# MK10D5 register map
File version: 1.6
Registers are 8-bit, read-write, reset 0x0 unless marked. A register's access mark holds for its fields unless they carry their own. Offsets are from the block's base; [hi:lo] are bit positions; {n}, {i} and the like mark numbered series; 'fields as' and 'values as' point back to an identical list.

## DMA — Enhanced direct memory access controller
Base 0x40008000; register names take the prefix DMA_
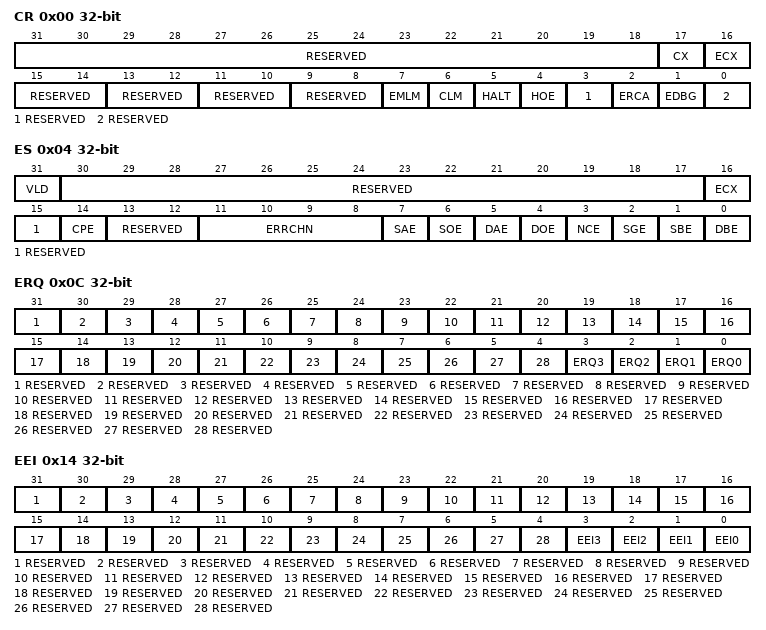
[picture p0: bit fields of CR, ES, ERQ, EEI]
0x00 CR 32-bit access per field — Control Register
  [31:18] RESERVED ro
  [17] CX rw — Cancel Transfer
    0=Normal operation; 1=Cancel the remaining data transfer. Stop the executing channel and force the minor loop to finish. The cancel takes effect after the last write of the current read/write sequence. The CX bit clears itself after the cancel has been honored. This cancel retires the channel normally as if the minor loop was completed.
  [16] ECX rw — Error Cancel Transfer
    0=Normal operation; 1=Cancel the remaining data transfer in the same fashion as the CX bit. Stop the executing channel and force the minor loop to finish. The cancel takes effect after the last write of the current read/write sequence. The ECX bit clears itself after the cancel is honored. In addition to cancelling the transfer, ECX treats the cancel as an error condition, thus updating the ES register and generating an optional error interrupt.
  [15:14] RESERVED ro
  [13:12] RESERVED ro
  [11:10] RESERVED ro
  [9:8] RESERVED ro
  [7] EMLM rw — Enable Minor Loop Mapping
    0=Disabled. TCDn.word2 is defined as a 32-bit NBYTES field.; 1=Enabled. TCDn.word2 is redefined to include individual enable fields, an offset field, and the NBYTES field. The individual enable fields allow the minor loop offset to be applied to the source address, the destination address, or both. The NBYTES field is reduced when either offset is enabled.
  [6] CLM rw — Continuous Link Mode
    0=A minor loop channel link made to itself goes through channel arbitration before being activated again; 1=A minor loop channel link made to itself does not go through channel arbitration before being activated again. Upon minor loop completion, the channel activates again if that channel has a minor loop channel link enabled and the link channel is itself. This effectively applies the minor loop offsets and restarts the next minor loop.
  [5] HALT rw — Halt DMA Operations
    0=Normal operation; 1=Stall the start of any new channels. Executing channels are allowed to complete. Channel execution resumes when this bit is cleared.
  [4] HOE rw — Halt On Error
    0=Normal operation; 1=Any error causes the HALT bit to set. Subsequently, all service requests are ignored until the HALT bit is cleared.
  [3] RESERVED ro
  [2] ERCA rw — Enable Round Robin Channel Arbitration
    0=Fixed priority arbitration is used for channel selection; 1=Round robin arbitration is used for channel selection
  [1] EDBG rw — Enable Debug
    0=When in debug mode, the DMA continues to operate; 1=When in debug mode, the DMA stalls the start of a new channel. Executing channels are allowed to complete. Channel execution resumes when the system exits debug mode or the EDBG bit is cleared.
  [0] RESERVED ro
0x04 ES 32-bit ro — Error Status Register
  [31] VLD
    0=No ERR bits are set; 1=At least one ERR bit is set indicating a valid error exists that has not been cleared
  [30:17] RESERVED
  [16] ECX — Transfer Cancelled
    0=No cancelled transfers; 1=The last recorded entry was a cancelled transfer by the error cancel transfer input
  [15] RESERVED
  [14] CPE — Channel Priority Error
    0=No channel priority error; 1=The last recorded error was a configuration error in the channel priorities. Channel priorities are not unique.
  [13:12] RESERVED
  [11:8] ERRCHN — Error Channel Number or Cancelled Channel Number
  [7] SAE — Source Address Error
    0=No source address configuration error; 1=The last recorded error was a configuration error detected in the TCDn_SADDR field. TCDn_SADDR is inconsistent with TCDn_ATTR[SSIZE].
  [6] SOE — Source Offset Error
    0=No source offset configuration error; 1=The last recorded error was a configuration error detected in the TCDn_SOFF field. TCDn_SOFF is inconsistent with TCDn_ATTR[SSIZE].
  [5] DAE — Destination Address Error
    0=No destination address configuration error; 1=The last recorded error was a configuration error detected in the TCDn_DADDR field. TCDn_DADDR is inconsistent with TCDn_ATTR[DSIZE].
  [4] DOE — Destination Offset Error
    0=No destination offset configuration error; 1=The last recorded error was a configuration error detected in the TCDn_DOFF field. TCDn_DOFF is inconsistent with TCDn_ATTR[DSIZE].
  [3] NCE — NBYTES/CITER Configuration Error
    0=No NBYTES/CITER configuration error; 1=The last recorded error was a configuration error detected in the TCDn_NBYTES or TCDn_CITER fields. TCDn_NBYTES is not a multiple of TCDn_ATTR[SSIZE] and TCDn_ATTR[DSIZE], or TCDn_CITER[CITER] is equal to zero, or TCDn_CITER[ELINK] is not equal to TCDn_BITER[ELINK]
  [2] SGE — Scatter/Gather Configuration Error
    0=No scatter/gather configuration error; 1=The last recorded error was a configuration error detected in the TCDn_DLASTSGA field. This field is checked at the beginning of a scatter/gather operation after major loop completion if TCDn_CSR[ESG] is enabled. TCDn_DLASTSGA is not on a 32 byte boundary.
  [1] SBE — Source Bus Error
    0=No source bus error; 1=The last recorded error was a bus error on a source read
  [0] DBE — Destination Bus Error
    0=No destination bus error; 1=The last recorded error was a bus error on a destination write
0x0C ERQ 32-bit — Enable Request Register
  [31] RESERVED
  [30] RESERVED
  [29] RESERVED
  [28] RESERVED
  [27] RESERVED
  [26] RESERVED
  [25] RESERVED
  [24] RESERVED
  [23] RESERVED
  [22] RESERVED
  [21] RESERVED
  [20] RESERVED
  [19] RESERVED
  [18] RESERVED
  [17] RESERVED
  [16] RESERVED
  [15] RESERVED
  [14] RESERVED
  [13] RESERVED
  [12] RESERVED
  [11] RESERVED
  [10] RESERVED
  [9] RESERVED
  [8] RESERVED
  [7] RESERVED
  [6] RESERVED
  [5] RESERVED
  [4] RESERVED
  [n] ERQ{n} (n=0..3) — Enable DMA Request {n}
    0=The DMA request signal for the corresponding channel is disabled; 1=The DMA request signal for the corresponding channel is enabled
0x14 EEI 32-bit — Enable Error Interrupt Register
  [31] RESERVED
  [30] RESERVED
  [29] RESERVED
  [28] RESERVED
  [27] RESERVED
  [26] RESERVED
  [25] RESERVED
  [24] RESERVED
  [23] RESERVED
  [22] RESERVED
  [21] RESERVED
  [20] RESERVED
  [19] RESERVED
  [18] RESERVED
  [17] RESERVED
  [16] RESERVED
  [15] RESERVED
  [14] RESERVED
  [13] RESERVED
  [12] RESERVED
  [11] RESERVED
  [10] RESERVED
  [9] RESERVED
  [8] RESERVED
  [7] RESERVED
  [6] RESERVED
  [5] RESERVED
  [4] RESERVED
  [n] EEI{n} (n=0..3) — Enable Error Interrupt {n}
    0=The error signal for corresponding channel does not generate an error interrupt; 1=The assertion of the error signal for corresponding channel generates an error interrupt request
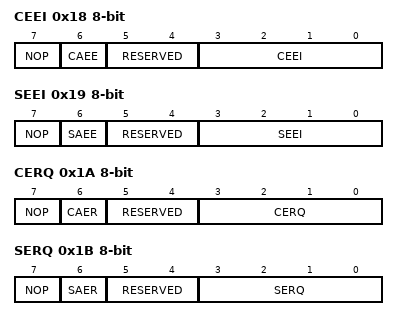
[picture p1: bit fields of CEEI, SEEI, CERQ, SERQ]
0x18 CEEI wo — Clear Enable Error Interrupt Register
  [7] NOP
    0=Normal operation; 1=No operation, ignore the other bits in this register
  [6] CAEE — Clear All Enable Error Interrupts
    0=Clear only the EEI bit specified in the CEEI field; 1=Clear all bits in EEI
  [5:4] RESERVED
  [3:0] CEEI — Clear Enable Error Interrupt
0x19 SEEI wo — Set Enable Error Interrupt Register
  [7] NOP
    values as CEEI.NOP
  [6] SAEE — Sets All Enable Error Interrupts
    0=Set only the EEI bit specified in the SEEI field; 1=Sets all bits in EEI
  [5:4] RESERVED
  [3:0] SEEI — Set Enable Error Interrupt
0x1A CERQ wo — Clear Enable Request Register
  [7] NOP
    values as CEEI.NOP
  [6] CAER — Clear All Enable Requests
    0=Clear only the ERQ bit specified in the CERQ field; 1=Clear all bits in ERQ
  [5:4] RESERVED
  [3:0] CERQ — Clear Enable Request
0x1B SERQ wo — Set Enable Request Register
  [7] NOP
    values as CEEI.NOP
  [6] SAER — Set All Enable Requests
    0=Set only the ERQ bit specified in the SERQ field; 1=Set all bits in ERQ
  [5:4] RESERVED
  [3:0] SERQ — Set enable request
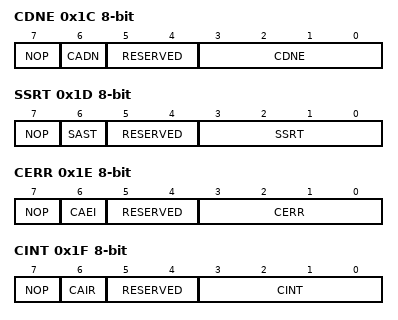
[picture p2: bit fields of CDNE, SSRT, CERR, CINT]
0x1C CDNE wo — Clear DONE Status Bit Register
  [7] NOP
    values as CEEI.NOP
  [6] CADN — Clears All DONE Bits
    0=Clears only the TCDn_CSR[DONE] bit specified in the CDNE field; 1=Clears all bits in TCDn_CSR[DONE]
  [5:4] RESERVED
  [3:0] CDNE — Clear DONE Bit
0x1D SSRT wo — Set START Bit Register
  [7] NOP
    values as CEEI.NOP
  [6] SAST — Set All START Bits (activates all channels)
    0=Set only the TCDn_CSR[START] bit specified in the SSRT field; 1=Set all bits in TCDn_CSR[START]
  [5:4] RESERVED
  [3:0] SSRT — Set START Bit
0x1E CERR wo — Clear Error Register
  [7] NOP
    values as CEEI.NOP
  [6] CAEI — Clear All Error Indicators
    0=Clear only the ERR bit specified in the CERR field; 1=Clear all bits in ERR
  [5:4] RESERVED
  [3:0] CERR — Clear Error Indicator
0x1F CINT wo — Clear Interrupt Request Register
  [7] NOP
    values as CEEI.NOP
  [6] CAIR — Clear All Interrupt Requests
    0=Clear only the INT bit specified in the CINT field; 1=Clear all bits in INT
  [5:4] RESERVED
  [3:0] CINT — Clear Interrupt Request
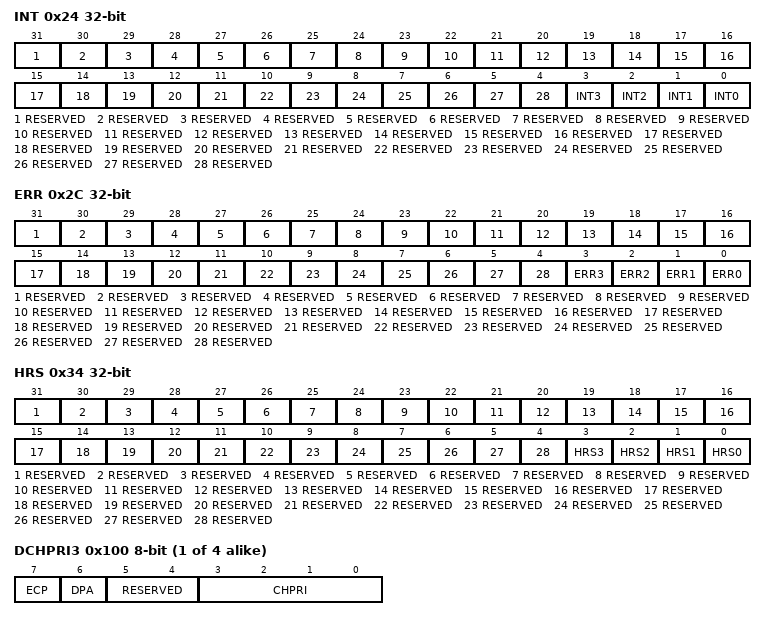
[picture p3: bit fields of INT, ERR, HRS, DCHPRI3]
0x24 INT 32-bit — Interrupt Request Register
  [31] RESERVED
  [30] RESERVED
  [29] RESERVED
  [28] RESERVED
  [27] RESERVED
  [26] RESERVED
  [25] RESERVED
  [24] RESERVED
  [23] RESERVED
  [22] RESERVED
  [21] RESERVED
  [20] RESERVED
  [19] RESERVED
  [18] RESERVED
  [17] RESERVED
  [16] RESERVED
  [15] RESERVED
  [14] RESERVED
  [13] RESERVED
  [12] RESERVED
  [11] RESERVED
  [10] RESERVED
  [9] RESERVED
  [8] RESERVED
  [7] RESERVED
  [6] RESERVED
  [5] RESERVED
  [4] RESERVED
  [n] INT{n} (n=0..3) — Interrupt Request {n}
    0=The interrupt request for corresponding channel is cleared; 1=The interrupt request for corresponding channel is active
0x2C ERR 32-bit — Error Register
  [31] RESERVED
  [30] RESERVED
  [29] RESERVED
  [28] RESERVED
  [27] RESERVED
  [26] RESERVED
  [25] RESERVED
  [24] RESERVED
  [23] RESERVED
  [22] RESERVED
  [21] RESERVED
  [20] RESERVED
  [19] RESERVED
  [18] RESERVED
  [17] RESERVED
  [16] RESERVED
  [15] RESERVED
  [14] RESERVED
  [13] RESERVED
  [12] RESERVED
  [11] RESERVED
  [10] RESERVED
  [9] RESERVED
  [8] RESERVED
  [7] RESERVED
  [6] RESERVED
  [5] RESERVED
  [4] RESERVED
  [n] ERR{n} (n=0..3) — Error In Channel {n}
    0=An error in the corresponding channel has not occurred; 1=An error in the corresponding channel has occurred
0x34 HRS 32-bit — Hardware Request Status Register
  [31] RESERVED
  [30] RESERVED
  [29] RESERVED
  [28] RESERVED
  [27] RESERVED
  [26] RESERVED
  [25] RESERVED
  [24] RESERVED
  [23] RESERVED
  [22] RESERVED
  [21] RESERVED
  [20] RESERVED
  [19] RESERVED
  [18] RESERVED
  [17] RESERVED
  [16] RESERVED
  [15] RESERVED
  [14] RESERVED
  [13] RESERVED
  [12] RESERVED
  [11] RESERVED
  [10] RESERVED
  [9] RESERVED
  [8] RESERVED
  [7] RESERVED
  [6] RESERVED
  [5] RESERVED
  [4] RESERVED
  [n] HRS{n} (n=0..3) — Hardware Request Status Channel {n}
    0=A hardware service request for the corresponding channel is not present; 1=A hardware service request for the corresponding channel is present
0x100 DCHPRI{x} (x=3,2,1,0; step 0x1) access per field reset not defined — Channel n Priority Register
  [7] ECP rw — Enable Channel Preemption
    0=Channel n cannot be suspended by a higher priority channel's service request; 1=Channel n can be temporarily suspended by the service request of a higher priority channel
  [6] DPA rw — Disable Preempt Ability
    0=Channel n can suspend a lower priority channel; 1=Channel n cannot suspend any channel, regardless of channel priority
  [5:4] RESERVED ro
  [3:0] CHPRI rw — Channel n Arbitration Priority
{0x1000+0x20*i} TCD{i}_SADDR (i=0..3) 32-bit reset not defined — TCD Source Address
  [31:0] SADDR — Source Address
{0x1004+0x20*i} TCD{i}_SOFF (i=0..3) 16-bit reset not defined — TCD Signed Source Address Offset
  [15:0] SOFF — Source address signed offset
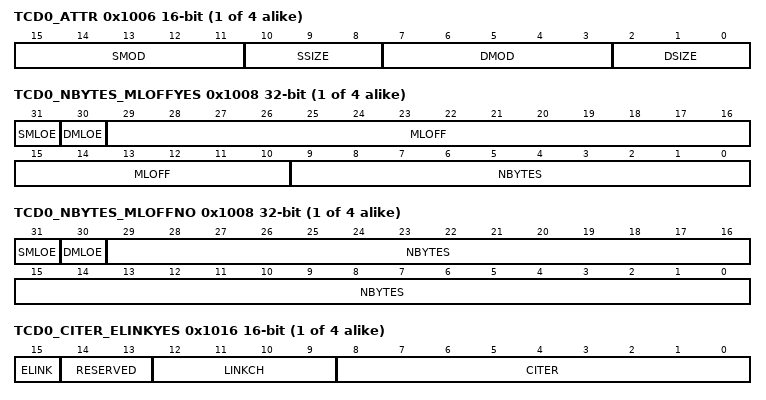
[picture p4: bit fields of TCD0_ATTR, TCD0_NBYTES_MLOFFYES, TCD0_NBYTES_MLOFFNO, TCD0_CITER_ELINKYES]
{0x1006+0x20*i} TCD{i}_ATTR (i=0..3) 16-bit reset not defined — TCD Transfer Attributes
  [15:11] SMOD — Source Address Modulo.
    0=Source address modulo feature is disabled
  [10:8] SSIZE — Source data transfer size
    0=8-bit; 1=16-bit; 2=32-bit; 4=16-byte
  [7:3] DMOD — Destination Address Modulo
  [2:0] DSIZE — Destination Data Transfer Size
{0x1008+0x20*i} TCD{i}_NBYTES_MLOFFYES (i=0..3) 32-bit reset not defined (DMA view) — TCD Signed Minor Loop Offset (Minor Loop and Offset Enabled)
  [31] SMLOE — Source Minor Loop Offset Enable
    0=The minor loop offset is not applied to the SADDR; 1=The minor loop offset is applied to the SADDR
  [30] DMLOE — Destination Minor Loop Offset enable
    0=The minor loop offset is not applied to the DADDR; 1=The minor loop offset is applied to the DADDR
  [29:10] MLOFF — If SMLOE or DMLOE is set, this field represents a sign-extended offset applied to the source or destination address to form the next-state value after the minor loop completes.
  [9:0] NBYTES — Minor Byte Transfer Count
{0x1008+0x20*i} TCD{i}_NBYTES_MLOFFNO (i=0..3) 32-bit reset not defined (DMA view) — TCD Signed Minor Loop Offset (Minor Loop Enabled and Offset Disabled)
  [31] SMLOE — Source Minor Loop Offset Enable
    values as TCD0_NBYTES_MLOFFYES.SMLOE
  [30] DMLOE — Destination Minor Loop Offset enable
    values as TCD0_NBYTES_MLOFFYES.DMLOE
  [29:0] NBYTES — Minor Byte Transfer Count
{0x1008+0x20*i} TCD{i}_NBYTES_MLNO (i=0..3) 32-bit reset not defined (DMA view) — TCD Minor Byte Count (Minor Loop Disabled)
  [31:0] NBYTES — Minor Byte Transfer Count
{0x100C+0x20*i} TCD{i}_SLAST (i=0..3) 32-bit reset not defined — TCD Last Source Address Adjustment
  [31:0] SLAST — Last source Address Adjustment
{0x1010+0x20*i} TCD{i}_DADDR (i=0..3) 32-bit reset not defined — TCD Destination Address
  [31:0] DADDR — Destination Address
{0x1014+0x20*i} TCD{i}_DOFF (i=0..3) 16-bit reset not defined — TCD Signed Destination Address Offset
  [15:0] DOFF — Destination Address Signed offset
{0x1016+0x20*i} TCD{i}_CITER_ELINKYES (i=0..3) 16-bit reset not defined (DMA view) — TCD Current Minor Loop Link, Major Loop Count (Channel Linking Enabled)
  [15] ELINK — Enable channel-to-channel linking on minor-loop complete
    0=The channel-to-channel linking is disabled; 1=The channel-to-channel linking is enabled
  [14:13] RESERVED
  [12:9] LINKCH — Link Channel Number
  [8:0] CITER — Current Major Iteration Count
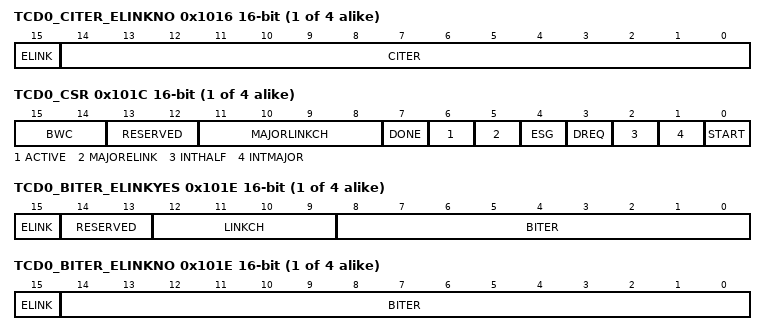
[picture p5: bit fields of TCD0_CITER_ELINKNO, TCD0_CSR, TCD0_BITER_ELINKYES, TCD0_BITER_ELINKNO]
{0x1016+0x20*i} TCD{i}_CITER_ELINKNO (i=0..3) 16-bit reset not defined (DMA view) — TCD Current Minor Loop Link, Major Loop Count (Channel Linking Disabled)
  [15] ELINK — Enable channel-to-channel linking on minor-loop complete
    values as TCD0_CITER_ELINKYES.ELINK
  [14:0] CITER — Current Major Iteration Count
{0x1018+0x20*i} TCD{i}_DLASTSGA (i=0..3) 32-bit reset not defined — TCD Last Destination Address Adjustment/Scatter Gather Address
{0x101C+0x20*i} TCD{i}_CSR (i=0..3) 16-bit reset not defined — TCD Control and Status
  [15:14] BWC — Bandwidth Control
    0=No eDMA engine stalls; 2=eDMA engine stalls for 4 cycles after each r/w; 3=eDMA engine stalls for 8 cycles after each r/w
  [13:12] RESERVED
  [11:8] MAJORLINKCH — Link Channel Number
  [7] DONE — Channel Done
  [6] ACTIVE — Channel Active
  [5] MAJORELINK — Enable channel-to-channel linking on major loop complete
    values as TCD0_CITER_ELINKYES.ELINK
  [4] ESG — Enable Scatter/Gather Processing
    0=The current channel's TCD is normal format; 1=The current channel's TCD specifies a scatter gather format. The DLASTSGA field provides a memory pointer to the next TCD to be loaded into this channel after the major loop completes its execution.
  [3] DREQ — Disable Request
    0=The channel's ERQ bit is not affected; 1=The channel's ERQ bit is cleared when the major loop is complete
  [2] INTHALF — Enable an interrupt when major counter is half complete.
    0=The half-point interrupt is disabled; 1=The half-point interrupt is enabled
  [1] INTMAJOR — Enable an interrupt when major iteration count completes
    0=The end-of-major loop interrupt is disabled; 1=The end-of-major loop interrupt is enabled
  [0] START — Channel Start
    0=The channel is not explicitly started; 1=The channel is explicitly started via a software initiated service request
{0x101E+0x20*i} TCD{i}_BITER_ELINKYES (i=0..3) 16-bit reset not defined (DMA view) — TCD Beginning Minor Loop Link, Major Loop Count (Channel Linking Enabled)
  [15] ELINK — Enables channel-to-channel linking on minor loop complete
    values as TCD0_CITER_ELINKYES.ELINK
  [14:13] RESERVED
  [12:9] LINKCH — Link Channel Number
  [8:0] BITER — Starting Major Iteration Count
{0x101E+0x20*i} TCD{i}_BITER_ELINKNO (i=0..3) 16-bit reset not defined (DMA view) — TCD Beginning Minor Loop Link, Major Loop Count (Channel Linking Disabled)
  [15] ELINK — Enables channel-to-channel linking on minor loop complete
    values as TCD0_CITER_ELINKYES.ELINK
  [14:0] BITER — Starting Major Iteration Count
